AUTOSAR XML (schema 4-3-0)
package /StartApplication/StartApplication_swc/DataTypes
  14 x impl type:
    EcuM_StateType: compu {15=ECUM_SUBSTATE_MASK, 16=ECUM_STATE_STARTUP, 17=ECUM_STATE_STARTUP_ONE, 18=ECUM_STATE_STARTUP_TWO, 32=ECUM_STATE_WAKEUP, 33=ECUM_STATE_WAKEUP_ONE, 34=ECUM_STATE_WAKEUP_VALIDATION, 35=ECUM_STATE_WAKEUP_REACTION, 36=ECUM_STATE_WAKEUP_TWO, 37=ECUM_STATE_WAKEUP_WAKESLEEP, 38=ECUM_STATE_WAKEUP_TTII, 48=ECUM_STATE_RUN, 50=ECUM_STATE_APP_RUN, 51=ECUM_STATE_APP_POST_RUN, 64=ECUM_STATE_SHUTDOWN, 68=ECUM_STATE_PREP_SHUTDOWN, 73=ECUM_STATE_GO_SLEEP, 77=ECUM_STATE_GO_OFF_ONE, 78=ECUM_STATE_GO_OFF_TWO, 80=ECUM_STATE_SLEEP, 128=ECUM_STATE_OFF, 144=ECUM_STATE_RESET}, implementation-data-type=uint8
    EcuM_SleepModeType: implementation-data-type=uint8
    EcuM_ShutdownCauseType: compu {0=ECUM_CAUSE_UNKNOWN, 1=ECUM_CAUSE_ECU_STATE, 2=ECUM_CAUSE_WDGM, 3=ECUM_CAUSE_DCM}, implementation-data-type=uint8
    ComM_ModeType: compu {0=COMM_NO_COMMUNICATION, 1=COMM_SILENT_COMMUNICATION, 2=COMM_FULL_COMMUNICATION}, implementation-data-type=uint8
    Dt_e2eGrp_ST_EST_grpMap_1efe9fd4: category=STRUCTURE
      6 x element, all with category=TYPE_REFERENCE, implementation-data-type=uint8:
        Re_ST_EST_dummy_16_23_2f274d97
        Re_sn_0d521c7c53964f869478fa5c12f4ec50_14_754efa353cf340fcb5ebf6a252677ba9_1_2f274d97
        Re_sn_0d521c7c53964f869478fa5c12f4ec50_14_4b5d00d65aef4a05b869d24584abb8c4_1_2f274d97
        Re_sn_0d521c7c53964f869478fa5c12f4ec50_14_8fcd25d281bf43f7836594d2433bdf22_11_2f274d97
        Re_sn_0d521c7c53964f869478fa5c12f4ec50_14_cab340b35df54638b5e0037eab93598a_8_2f274d97
        Re_sn_0d521c7c53964f869478fa5c12f4ec50_14_296a2827f3ac4a3cb35d9abfed66395a_2_2f274d97
    NvM_ServiceIdType: compu {6=NVM_READ_BLOCK, 7=NVM_WRITE_BLOCK, 8=NVM_RESTORE_BLOCK_DEFAULTS, 9=NVM_ERASE_BLOCK, 11=NVM_INVALIDATE_NV_BLOCK, 12=NVM_READ_ALL}, implementation-data-type=uint8
    NvM_RequestResultType: compu {0=NVM_REQ_OK, 1=NVM_REQ_NOT_OK, 2=NVM_REQ_PENDING, 3=NVM_REQ_INTEGRITY_FAILED, 4=NVM_REQ_BLOCK_SKIPPED, 5=NVM_REQ_NV_INVALIDATED, 6=NVM_REQ_CANCELED, 7=NVM_REQ_REDUNDANCY_FAILED, 8=NVM_REQ_RESTORED_FROM_ROM}, implementation-data-type=uint8
    Dem_EventStatusType: compu {0=DEM_EVENT_STATUS_PASSED, 1=DEM_EVENT_STATUS_FAILED, 2=DEM_EVENT_STATUS_PREPASSED, 3=DEM_EVENT_STATUS_PREFAILED, 4=DEM_EVENT_STATUS_FDC_THRESHOLD_REACHED}, implementation-data-type=uint8
    Dcm_Data2ByteType: category=ARRAY, sw-calibration-access=READ-ONLY
      element Dcm_Data2ByteTypeElement: array-size=2, array-size-semantics=FIXED-SIZE, implementation-data-type=uint8
    Dcm_NegativeResponseCodeType: compu {0=DCM_E_POSITIVERESPONSE, 16=DCM_E_GENERALREJECT, 17=DCM_E_SERVICENOTSUPPORTED, 18=DCM_E_SUBFUNCTIONNOTSUPPORTED, 19=DCM_E_INCORRECTMESSAGELENGTHORINVALIDFORMAT, 20=DCM_E_RESPONSETOOLONG, 33=DCM_E_BUSYREPEATREQUEST, 34=DCM_E_CONDITIONSNOTCORRECT, 36=DCM_E_REQUESTSEQUENCEERROR, 37=DCM_E_NORESPONSEFROMSUBNETCOMPONENT, 38=DCM_E_FAILUREPREVENTSEXECUTIONOFREQUESTEDACTION, 49=DCM_E_REQUESTOUTOFRANGE, 51=DCM_E_SECURITYACCESSDENIED, 53=DCM_E_INVALIDKEY, 54=DCM_E_EXCEEDNUMBEROFATTEMPTS, 55=DCM_E_REQUIREDTIMEDELAYNOTEXPIRED, 112=DCM_E_UPLOADDOWNLOADNOTACCEPTED, 113=DCM_E_TRANSFERDATASUSPENDED, 114=DCM_E_GENERALPROGRAMMINGFAILURE, 115=DCM_E_WRONGBLOCKSEQUENCECOUNTER, 120=DCM_E_REQUESTCORRECTLYRECEIVEDRESPONSEPENDING, 126=DCM_E_SUBFUNCTIONNOTSUPPORTEDINACTIVESESSION, 127=DCM_E_SERVICENOTSUPPORTEDINACTIVESESSION, 129=DCM_E_RPMTOOHIGH, 130=DCM_E_RPMTOOLOW, 131=DCM_E_ENGINEISRUNNING, 132=DCM_E_ENGINEISNOTRUNNING, 133=DCM_E_ENGINERUNTIMETOOLOW, 134=DCM_E_TEMPERATURETOOHIGH, 135=DCM_E_TEMPERATURETOOLOW, 136=DCM_E_VEHICLESPEEDTOOHIGH, 137=DCM_E_VEHICLESPEEDTOOLOW, 138=DCM_E_THROTTLE_PEDALTOOHIGH, 139=DCM_E_THROTTLE_PEDALTOOLOW, 140=DCM_E_TRANSMISSIONRANGENOTINNEUTRAL, 141=DCM_E_TRANSMISSIONRANGENOTINGEAR, 143=DCM_E_BRAKESWITCH_NOTCLOSED, 144=DCM_E_SHIFTERLEVERNOTINPARK, 145=DCM_E_TORQUECONVERTERCLUTCHLOCKED, 146=DCM_E_VOLTAGETOOHIGH, 147=DCM_E_VOLTAGETOOLOW}, implementation-data-type=uint8
    DataArray_Type_2: category=ARRAY, sw-calibration-access=READ-ONLY
      element DataArray_Type_2Element: array-size=2, array-size-semantics=FIXED-SIZE, implementation-data-type=uint8
    Dem_OperationCycleStateType: compu {0=DEM_CYCLE_STATE_START, 1=DEM_CYCLE_STATE_END}, implementation-data-type=uint8
    Dt_e2eGrp_AVL_PO_EPS_grpMap_0e78aaac: category=STRUCTURE
      8 x element, all with category=TYPE_REFERENCE:
        Re_sn_e0f63d36315c4773ba837e73d6faaadd_15_bc95b5ba2eae48218eb9877ea08559a2_2_828cc38e: implementation-data-type=uint8
        Re_sn_e0f63d36315c4773ba837e73d6faaadd_15_4fc18042a3ed4ed3935aa3b3038bf544_5_828cc38e: implementation-data-type=uint16
        Re_sn_e0f63d36315c4773ba837e73d6faaadd_15_99fd6a6f88664f46a45dae1eac3e4bb9_5_828cc38e: implementation-data-type=uint16
        Re_sn_e0f63d36315c4773ba837e73d6faaadd_15_c5c4fc12c19449dca31982abd0f99bbb_2_828cc38e: implementation-data-type=uint8
        Re_sn_e0f63d36315c4773ba837e73d6faaadd_15_2de5d882792e4739a95de3e1c7b8ccad_10_828cc38e: implementation-data-type=uint8
        Re_sn_e0f63d36315c4773ba837e73d6faaadd_15_accb41f44683494d8bbe73645993b2b8_9_828cc38e: implementation-data-type=uint16
        Re_sn_e0f63d36315c4773ba837e73d6faaadd_15_7184c8825a7a44dd9a0b76c751498b8c_6_828cc38e: implementation-data-type=uint8
        Re_sn_e0f63d36315c4773ba837e73d6faaadd_15_7f90cd4f694b47ba8781390120dcbc0a_3_828cc38e: implementation-data-type=uint8
    WdgM_CheckpointIdType: implementation-data-type=uint16
package /StartApplication/StartApplication_swc/Interfaces
  client server interface PiEcuM_ShutdownTarget: is-service=true, service-kind=VENDOR-SPECIFIC
    5 x operation, all with possible-error=PiEcuM_ShutdownTarget/E_NOT_OK:
      SelectShutdownTarget
        arg targetState: type=EcuM_StateType, direction=IN
        arg resetSleepMode: type=EcuM_SleepModeType, direction=IN
      GetShutdownTarget
        arg target: type=EcuM_StateType, direction=OUT
        arg resetSleepMode: type=EcuM_SleepModeType, direction=OUT
      GetLastShutdownTarget
        arg target: type=EcuM_StateType, direction=OUT
        arg resetSleepMode: type=EcuM_SleepModeType, direction=OUT
      SelectShutdownCause
        arg shutdownCause: type=EcuM_ShutdownCauseType, direction=IN
      GetShutdownCause
        arg shutdownCause: type=EcuM_ShutdownCauseType, direction=OUT
    error E_NOT_OK: error-code=1
  client server interface PiUR_USR_A_FlexRay_5b5a9ac2: is-service=true, service-kind=VENDOR-SPECIFIC
    4 x operation:
      GetCurrentComMode: possible-error=PiUR_USR_A_FlexRay_5b5a9ac2/E_NOT_OK
        arg ComMode: type=ComM_ModeType, direction=OUT
      GetMaxComMode: possible-error=PiUR_USR_A_FlexRay_5b5a9ac2/E_NOT_OK
        arg ComMode: type=ComM_ModeType, direction=OUT
      GetRequestedComMode: possible-error=PiUR_USR_A_FlexRay_5b5a9ac2/E_NOT_OK
        arg ComMode: type=ComM_ModeType, direction=OUT
      RequestComMode: possible-error=[PiUR_USR_A_FlexRay_5b5a9ac2/E_NOT_OK, E_MODE_LIMITATION]
        arg ComMode: type=ComM_ModeType, direction=IN
    error E_NOT_OK: error-code=1
    error E_MODE_LIMITATION: error-code=2
  sender receiver interface Pie2eGrp_ST_EST_grpMap_1efe9fd4
    data Dee2eGrp_ST_EST_grpMap_1efe9fd4: type=Dt_e2eGrp_ST_EST_grpMap_1efe9fd4
  sender receiver interface Pisn_209e4b614ee044c4bbf1020e8ad2a6e0_10_d2a8dd49e0f74a499b91350a40cf3a4b_5_605eb7ca
    data Desn_209e4b614ee044c4bbf1020e8ad2a6e0_10_d2a8dd49e0f74a499b91350a40cf3a4b_5_605eb7ca: type=uint32
  sender receiver interface Pisn_acb3c9a426bf4887ba724efd428ad5a4_3_ad2096213c0c47a78c10b4a8c5667464_7_7e6a2fc7
    data Desn_acb3c9a426bf4887ba724efd428ad5a4_3_ad2096213c0c47a78c10b4a8c5667464_7_7e6a2fc7: type=uint32
  6 x client server interface, all with is-service=true, service-kind=VENDOR-SPECIFIC:
    PiNvmDataPort
      operation WriteBlock: possible-error=PiNvmDataPort/E_NOT_OK
        arg SrcPtr: type=dtRef_const_VOID, direction=IN
      operation ReadBlock: possible-error=PiNvmDataPort/E_NOT_OK
        arg DstPtr: type=dtRef_VOID, direction=IN
      error E_NOT_OK: error-code=1
    PiNvmJobFinishedPort
      operation JobFinished
        arg ServiceId: type=NvM_ServiceIdType, direction=IN
        arg JobResult: type=NvM_RequestResultType, direction=IN
    PiDiagnosticMonitor_DEM_EVENT_StartApplication
      operation SetEventStatus: possible-error=PiDiagnosticMonitor_DEM_EVENT_StartApplication/E_NOT_OK
        arg EventStatus: type=Dem_EventStatusType, direction=IN
      operation ResetEventStatus: possible-error=PiDiagnosticMonitor_DEM_EVENT_StartApplication/E_NOT_OK
      error E_NOT_OK: error-code=1
    PiDcmDataService_DID_StartApplication
      operation WriteData
        arg Data: type=Dcm_Data2ByteType, direction=IN
        arg ErrorCode: type=Dcm_NegativeResponseCodeType, direction=OUT
      operation ReadData
        arg Data: type=Dcm_Data2ByteType, direction=OUT
      operation ConditionCheckRead
        arg ErrorCode: type=Dcm_NegativeResponseCodeType, direction=OUT
    PiDemDataService_DemDataElementClass_StartApplication
      operation ReadData
        arg Data: type=DataArray_Type_2, direction=OUT
    PiDemOpCycle_NON_OBD
      operation SetOperationCycleState: possible-error=PiDemOpCycle_NON_OBD/E_NOT_OK
        arg CycleState: type=Dem_OperationCycleStateType, direction=IN
      error E_NOT_OK: error-code=1
  sender receiver interface Pie2eGrp_AVL_PO_EPS_grpMap_0e78aaac
    data Dee2eGrp_AVL_PO_EPS_grpMap_0e78aaac: type=Dt_e2eGrp_AVL_PO_EPS_grpMap_0e78aaac
  client server interface PiAliveWdgMSupervisedEntity_StartApplication: is-service=true, service-kind=VENDOR-SPECIFIC
    operation CheckpointReached: possible-error=PiAliveWdgMSupervisedEntity_StartApplication/E_NOT_OK
      arg checkpointId: type=WdgM_CheckpointIdType, direction=IN
    error E_NOT_OK: error-code=1
package /StartApplication/StartApplication_swc/ComponentTypes
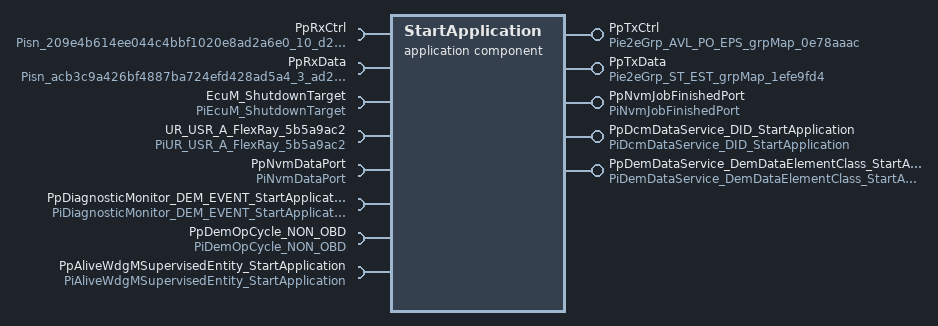
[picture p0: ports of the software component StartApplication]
  application sw component type StartApplication
    4 x require port:
      PpRxCtrl: nonqueued-receiver-com-spec{data-element=Desn_209e4b614ee044c4bbf1020e8ad2a6e0_10_d2a8dd49e0f74a499b91350a40cf3a4b_5_605eb7ca, handle-out-of-range-status=SILENT, init-value=0}, required-interface=Pisn_209e4b614ee044c4bbf1020e8ad2a6e0_10_d2a8dd49e0f74a499b91350a40cf3a4b_5_605eb7ca
      PpRxData: nonqueued-receiver-com-spec{data-element=Desn_acb3c9a426bf4887ba724efd428ad5a4_3_ad2096213c0c47a78c10b4a8c5667464_7_7e6a2fc7, handle-out-of-range-status=SILENT, init-value=0}, required-interface=Pisn_acb3c9a426bf4887ba724efd428ad5a4_3_ad2096213c0c47a78c10b4a8c5667464_7_7e6a2fc7
      EcuM_ShutdownTarget: required-interface=PiEcuM_ShutdownTarget
      UR_USR_A_FlexRay_5b5a9ac2: required-interface=PiUR_USR_A_FlexRay_5b5a9ac2
    provide port PpTxCtrl: nonqueued-sender-com-spec{data-element=Dee2eGrp_AVL_PO_EPS_grpMap_0e78aaac, init-value=fields=[0, 0, 0, 0, 0, 0, 0, 0]}, provided-interface=Pie2eGrp_AVL_PO_EPS_grpMap_0e78aaac
    provide port PpTxData: nonqueued-sender-com-spec{data-element=Dee2eGrp_ST_EST_grpMap_1efe9fd4, init-value=fields=[255, 0, 0, 0, 0, 0]}, provided-interface=Pie2eGrp_ST_EST_grpMap_1efe9fd4
    provide port PpNvmJobFinishedPort: provided-interface=PiNvmJobFinishedPort
    require port PpNvmDataPort: required-interface=PiNvmDataPort
    require port PpDiagnosticMonitor_DEM_EVENT_StartApplication: required-interface=PiDiagnosticMonitor_DEM_EVENT_StartApplication
    provide port PpDcmDataService_DID_StartApplication: provided-interface=PiDcmDataService_DID_StartApplication
    provide port PpDemDataService_DemDataElementClass_StartApplication: provided-interface=PiDemDataService_DemDataElementClass_StartApplication
    require port PpDemOpCycle_NON_OBD: required-interface=PiDemOpCycle_NON_OBD
    require port PpAliveWdgMSupervisedEntity_StartApplication: required-interface=PiAliveWdgMSupervisedEntity_StartApplication
    behavior StartApplicationInternalBehavior: handle-termination-and-restart=NO-SUPPORT
      4 x timing event:
        Timer_StartApplication_Cyclic1ms: start-on-event=StartApplication_Cyclic1ms, period=0.001
        Timer_StartApplication_Cyclic10ms: start-on-event=StartApplication_Cyclic10ms, period=0.01
        Timer_StartApplication_Cyclic250ms: start-on-event=StartApplication_Cyclic250ms, period=0.25
        Timer_StartApplication_Cyclic1000ms: start-on-event=StartApplication_Cyclic1000ms, period=1
      init event Timer_StartApplication_Init: start-on-event=StartApplication_Init
      data received event DataReceivedEvent_StartApplication_OnDataRec_RxCtrl_PpRxCtrl_Desn_209e4b614ee044c4bbf1020e8ad2a6e0_10_d2a8dd49e0f74a499_73627d40: start-on-event=StartApplication_OnDataRec_RxCtrl, data=PpRxCtrl.Desn_209e4b614ee044c4bbf1020e8ad2a6e0_10_d2a8dd49e0f74a499b91350a40cf3a4b_5_605eb7ca
      data received event DataReceivedEvent_StartApplication_OnDataRec_RxData_PpRxData_Desn_acb3c9a426bf4887ba724efd428ad5a4_3_ad2096213c0c47a78c_7fa235e9: start-on-event=StartApplication_OnDataRec_RxData, data=PpRxData.Desn_acb3c9a426bf4887ba724efd428ad5a4_3_ad2096213c0c47a78c10b4a8c5667464_7_7e6a2fc7
      5 x operation invoked event:
        OpEventStartApplication_MEM_JobFinished_JobFinished_PpNvmJobFinishedPort: start-on-event=StartApplication_MEM_JobFinished, operation=PpNvmJobFinishedPort.JobFinished
        OpEventStartApplication_DIAG_DcmReadData_ReadData_PpDcmDataService_DID_StartApplication: start-on-event=StartApplication_DIAG_DcmReadData, operation=PpDcmDataService_DID_StartApplication.ReadData
        OpEventStartApplication_DIAG_DcmWriteData_WriteData_PpDcmDataService_DID_StartApplication: start-on-event=StartApplication_DIAG_DcmWriteData, operation=PpDcmDataService_DID_StartApplication.WriteData
        OpEventStartApplication_DIAG_ConditionCheckRead_ConditionCheckRead_PpDcmDataService_DID_StartApplication: start-on-event=StartApplication_DIAG_ConditionCheckRead, operation=PpDcmDataService_DID_StartApplication.ConditionCheckRead
        OpEventStartApplication_DIAG_DemReadData_ReadData_PpDemDataService_DemDataElementClass_StartApplication: start-on-event=StartApplication_DIAG_DemReadData, operation=PpDemDataService_DemDataElementClass_StartApplication.ReadData
      explicit-inter-runnable-variables:
        data IrvOccuranceCounterDid: type=uint16, init-value=0
      port-api-options:
        enable-take-address=true, indirect-api=false, port=EcuM_ShutdownTarget
        enable-take-address=true, indirect-api=false, port=UR_USR_A_FlexRay_5b5a9ac2
        enable-take-address=true, indirect-api=false, port=PpRxCtrl
        enable-take-address=true, indirect-api=false, port=PpRxData
        enable-take-address=true, indirect-api=false, port=PpTxData
        enable-take-address=true, indirect-api=false, port=PpNvmJobFinishedPort
        enable-take-address=true, indirect-api=false, port=PpNvmDataPort
        enable-take-address=true, indirect-api=false, port=PpDiagnosticMonitor_DEM_EVENT_StartApplication
        enable-take-address=true, indirect-api=false, port=PpDcmDataService_DID_StartApplication
        enable-take-address=true, indirect-api=false, port=PpDemDataService_DemDataElementClass_StartApplication
        enable-take-address=true, indirect-api=false, port=PpDemOpCycle_NON_OBD
        enable-take-address=true, indirect-api=false, port=PpTxCtrl
        enable-take-address=true, indirect-api=false, port=PpAliveWdgMSupervisedEntity_StartApplication
      12 x runnable:
        StartApplication_Cyclic1ms
        StartApplication_Cyclic10ms
          sync call OpServerCallStartApplication_Cyclic10ms_CheckpointReached_PpAliveWdgMSupervisedEntity_StartApplication: operation=PpAliveWdgMSupervisedEntity_StartApplication.CheckpointReached, timeout=0
        StartApplication_Cyclic250ms
          data-receive-point-by-arguments:
            access DataReceivePointStartApplication_Cyclic250ms_PpRxData_Desn_acb3c9a426bf4887ba724efd428ad5a4_3_ad2096213c0c47a78c10b4a8c_3e386414: accessed-variable=PpRxData.Desn_acb3c9a426bf4887ba724efd428ad5a4_3_ad2096213c0c47a78c10b4a8c5667464_7_7e6a2fc7
          data-send-points:
            access DataSendPointStartApplication_Cyclic250ms_PpTxData_Dee2eGrp_ST_EST_grpMap_1efe9fd4: accessed-variable=PpTxData.Dee2eGrp_ST_EST_grpMap_1efe9fd4
            access DataSendPointStartApplication_Cyclic250ms_PpTxCtrl_Dee2eGrp_AVL_PO_EPS_grpMap_0e78aaac: accessed-variable=PpTxCtrl.Dee2eGrp_AVL_PO_EPS_grpMap_0e78aaac
          read-local-variables:
            access StartApplication_Cyclic250ms_IrvOccuranceCounterDid_DIRECT_READ: accessed-variable=IrvOccuranceCounterDid
          sync call OpServerCallStartApplication_Cyclic250ms_GetCurrentComMode_UR_USR_A_FlexRay_5b5a9ac2: operation=UR_USR_A_FlexRay_5b5a9ac2.GetCurrentComMode, timeout=0
          sync call OpServerCallStartApplication_Cyclic250ms_RequestComMode_UR_USR_A_FlexRay_5b5a9ac2: operation=UR_USR_A_FlexRay_5b5a9ac2.RequestComMode, timeout=0
          sync call OpServerCallStartApplication_Cyclic250ms_ReadBlock_PpNvmDataPort: operation=PpNvmDataPort.ReadBlock, timeout=0
        StartApplication_Cyclic1000ms
        StartApplication_Init: can-be-invoked-concurrently=true
          sync call OpServerCallStartApplication_Init_RequestComMode_UR_USR_A_FlexRay_5b5a9ac2: operation=UR_USR_A_FlexRay_5b5a9ac2.RequestComMode, timeout=0
        StartApplication_OnDataRec_RxCtrl
          data-receive-point-by-arguments:
            access DataReceivePointStartApplication_OnDataRec_RxCtrl_PpRxCtrl_Desn_209e4b614ee044c4bbf1020e8ad2a6e0_10_d2a8dd49e0f74a499b9_ec618e8e: accessed-variable=PpRxCtrl.Desn_209e4b614ee044c4bbf1020e8ad2a6e0_10_d2a8dd49e0f74a499b91350a40cf3a4b_5_605eb7ca
          data-send-points:
            access DataSendPointStartApplication_OnDataRec_RxCtrl_PpTxCtrl_Dee2eGrp_AVL_PO_EPS_grpMap_0e78aaac: accessed-variable=PpTxCtrl.Dee2eGrp_AVL_PO_EPS_grpMap_0e78aaac
          sync call OpServerCallStartApplication_OnDataRec_RxCtrl_SetOperationCycleState_PpDemOpCycle_NON_OBD: operation=PpDemOpCycle_NON_OBD.SetOperationCycleState, timeout=0
        StartApplication_OnDataRec_RxData
          data-receive-point-by-arguments:
            access DataReceivePointStartApplication_OnDataRec_RxData_PpRxData_Desn_acb3c9a426bf4887ba724efd428ad5a4_3_ad2096213c0c47a78c10_c3b55eaf: accessed-variable=PpRxData.Desn_acb3c9a426bf4887ba724efd428ad5a4_3_ad2096213c0c47a78c10b4a8c5667464_7_7e6a2fc7
          data-send-points:
            access DataSendPointStartApplication_OnDataRec_RxData_PpTxCtrl_Dee2eGrp_AVL_PO_EPS_grpMap_0e78aaac: accessed-variable=PpTxCtrl.Dee2eGrp_AVL_PO_EPS_grpMap_0e78aaac
          read-local-variables:
            access StartApplication_OnDataRec_RxData_IrvOccuranceCounterDid_DIRECT_READ: accessed-variable=IrvOccuranceCounterDid
          sync call OpServerCallStartApplication_OnDataRec_RxData_SelectShutdownTarget_EcuM_ShutdownTarget: operation=EcuM_ShutdownTarget.SelectShutdownTarget, timeout=0
          sync call OpServerCallStartApplication_OnDataRec_RxData_WriteBlock_PpNvmDataPort: operation=PpNvmDataPort.WriteBlock, timeout=0
          sync call OpServerCallStartApplication_OnDataRec_RxData_SetEventStatus_PpDiagnosticMonitor_DEM_EVENT_StartApplication: operation=PpDiagnosticMonitor_DEM_EVENT_StartApplication.SetEventStatus, timeout=0
          written-local-variables:
            access StartApplication_OnDataRec_RxData_IrvOccuranceCounterDid_DIRECT_WRITE: accessed-variable=IrvOccuranceCounterDid
        StartApplication_MEM_JobFinished: can-be-invoked-concurrently=true
          data-send-points:
            access DataSendPointStartApplication_MEM_JobFinished_PpTxCtrl_Dee2eGrp_AVL_PO_EPS_grpMap_0e78aaac: accessed-variable=PpTxCtrl.Dee2eGrp_AVL_PO_EPS_grpMap_0e78aaac
        StartApplication_DIAG_DcmReadData: can-be-invoked-concurrently=true
          read-local-variables:
            access StartApplication_DIAG_DcmReadData_IrvOccuranceCounterDid_DIRECT_READ: accessed-variable=IrvOccuranceCounterDid
        StartApplication_DIAG_DcmWriteData: can-be-invoked-concurrently=true
          written-local-variables:
            access StartApplication_DIAG_DcmWriteData_IrvOccuranceCounterDid_DIRECT_WRITE: accessed-variable=IrvOccuranceCounterDid
        StartApplication_DIAG_ConditionCheckRead: can-be-invoked-concurrently=true
        StartApplication_DIAG_DemReadData: can-be-invoked-concurrently=true
          read-local-variables:
            access StartApplication_DIAG_DemReadData_IrvOccuranceCounterDid_DIRECT_READ: accessed-variable=IrvOccuranceCounterDid
  swc implementation StartApplicationImplementation: programming-language=C, behavior=StartApplicationInternalBehavior
